AUTOSAR XML (schema 4-2-2)
package /AUTOLIV/SoftwareComponents/ACC
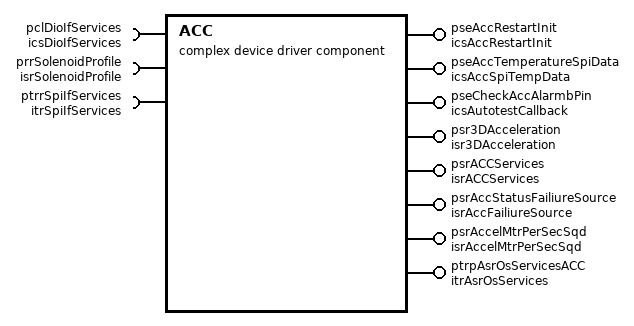
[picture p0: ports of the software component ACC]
  complex device driver sw component type ACC: category=MCAL_Communication_Abstraction
    require port pclDioIfServices: required-com-specs=[ReadChannel, WriteChannel], required-interface=icsDioIfServices  # # Architecture Element ID - ARCH_SW_ACC_pclDioIfServices # Description - The interface shall be used to read the state of ALARMB pin of TDK chip. # Data Flow ## Inputs - {u8ChannelID} - the ID of GPIO channel. ## Outputs - {u8Level} - the level of GPIO pin. # Linked Runnable - ACC_runMainFunction #Traceability
    require port prrSolenoidProfile: nonqueued-receiver-com-spec{data-element=au8SelectedProfile, init-value=6 x KU8_PROFILE_UNLOCK}, required-interface=isrSolenoidProfile
    8 x provide port:
      pseAccRestartInit: server-com-spec{operation=RestartInitialization, queue-length=1}, provided-interface=icsAccRestartInit  # # Architecture Element ID - ARCH_SW_ACC_pseAccRestartInit # Description - The runnable shall be used to restart the initialization sequence of TDK chip when ECU is restore from sleep mode. # Data Flow ## Inputs ## Outputs # Linked Runnable - ACC_RestartInitialization #Traceability
      pseAccTemperatureSpiData: server-com-spec{operation=GetTemperatureData, queue-length=1}, provided-interface=icsAccSpiTempData  # # Architecture Element ID - ARCH_SW_ACC_pseAccTemperatureSpiData # Description - The runnable shall communicate the raw register value for the temperature read from the TDK chip. # Data Flow ## Inputs ## Outputs - {Raw Temperature} # Linked Runnable - ACC_GetAccelerometerTemperature #Traceability
      pseCheckAccAlarmbPin: server-com-spec{operation=AutotestCallback, queue-length=1}, provided-interface=icsAutotestCallback  # Architecture Element ID - ARCH_SW_ACC_pseCheckAccAlarmbPin # Description - The autotest shall check if the ALARMB pin of the TDK accelerometer chip has been activated; - If any of the x, y, z axes of accelerometer have 30 consecutive identical values, - If the sequence of the ALARMB pin at initialisation is within the nominal timing parameters, - If any bit from alarm register is qualified. - Also the autotest shall check the two bits of return status from the Spi response and also checking if a Spi response has a wrong CRC. - If one or more bits of status information are qualified within 100ms then the result of autotest shall be NOK # Data Flow ## Inputs ## Outputs - {Autotest Result} - Can be one of the following values: OK, NOK, NOT DECIDED # Linked Runnable - ACC_Autotest_CheckAlarmbPin #Traceability DOM_eCS_TF_H_318 DOM_eCS_TF_H_319 DOM_eCS_TF_H_320
      psr3DAcceleration: nonqueued-sender-com-spec{data-element=st3DAccel, uses-end-to-end-protection=0, init-value=fields=[0, 0, 0]}, provided-interface=isr3DAcceleration  # # Architecture Element ID - ARCH_SW_ACC_psr3DAcceleration # Description - The runnable shall read the acceleration values for the x,y,z axis and communicate them to the rest of the Application raw values # Data Flow ## Inputs ## Outputs - {Acceleration} - Unit: g # Linked Runnable - ACC_runMainFunction #Traceability
      psrACCServices: nonqueued-sender-com-spec{data-element=u8AccInitStateMachine, uses-end-to-end-protection=0, init-value=0}, provided-interface=isrACCServices  # # Architecture Element ID - ARCH_SW_ACC_psrACCServices # Description - The runnable shall read the value of ACC initialization state machine index. # Data Flow ## Inputs - {acc_u8AccInitSM} - Variable used in ACC initialization state machine. ## Outputs # Linked Runnable - ACC_runMainFunction #Traceability
      psrAccStatusFailiureSource: provided-interface=isrAccFailiureSource  # # Architecture Element ID - ARCH_SW_ACC_psrAccStatusFailiureSource_u32AccAlarmRegStatus # Description - The runnable shall read all the data from alarm registers of accelerometer and write them to the {AlarmRegistersUsefulData} output parameter. # Data Flow ## Inputs ## Outputs - {AlarmRegistersUsefulData} - Unit: mapped bits # Linked Runnable - ACC_runMainFunction #Traceability FUSA_SM_ACC_DS-000342_IAM-20685_148 FUSA_SM_ACC_DS-000342_IAM-20685_149 FUSA_SM_ACC_DS-000342_IAM-20685_150 FUSA_SM_ACC_DS-000342_IAM-20685_151 DOM_eCS_TF_H_369 DOM_eCS_TF_H_359 DOM_eCS_TF_H_355 -------------------------------------------------------------------------------------------- # Architecture Element ID - ARCH_SW_ACC_psrAccStatusFailiureSource_u8AccReturnStatus # Description - The runnable shall read the two bits of return status received from Spi response of accelerometer. # Data Flow ## Inputs ## Outputs - {ReturnStatus} - Unit: two bits # Linked Runnable - ACC_runMainFunction #Traceability FUSA_SM_ACC_DS-000342_IAM-20685_134 --------------------------------------------------------------------------------------------- # Architecture Element ID - ARCH_SW_ACC_psrAccStatusFailiureSource_u8AccCRCStatus # Description - The runnable shall read the error status of CRC received from accelerometer. # Data Flow ## Inputs ## Outputs - {CRCStatus} - Unit: flag # Linked Runnable - ACC_runMainFunction #Traceability DOM_eCS_TF_H_318, DOM_eCS_TF_H_319 FUSA_SM_ACC_DS-000342_IAM-20685_134 ---------------------------------------------------------------------------------------------- # Architecture Element ID - ARCH_SW_ACC_psrAccStatusFailiureSource_u8AccAlarmbPreinitSeqStatus # Description - The runnable shall read the error status of ALARMB pin sequence at initialisation. # Data Flow ## Inputs ## Outputs - {AlarmbPreinitSeqStatus} - Unit: flag # Linked Runnable - ACC_runMainFunction #Traceability FUSA_SM_ACC_DS-000342_IAM-20685_128 FUSA_SM_ACC_DS-000342_IAM-20685_129 FUSA_SM_ACC_DS-000342_IAM-20685_130 FUSA_SM_ACC_DS-000342_IAM-20685_131 FUSA_SM_ACC_DS-000342_IAM-20685_132 FUSA_SM_ACC_DS-000342_IAM-20685_133 ---------------------------------------------------------------------------------------------- # Architecture Element ID - ARCH_SW_ACC_psrAccStatusFailiureSource_u8AccelAxisBroken # Description - The runnable shall read the error status of broken data from each accelerometer axis. # Data Flow ## Inputs ## Outputs - {AccelAxisBroken} - Unit: 3 flags (0b00000xyz) # Linked Runnable - ACC_runMainFunction #Traceability FUSA_SM_ACC_DS-000342_IAM-20685_141 ----------------------------------------------------------------------------------------------
        provided-com-specs:
          data-element=u32AccAlarmRegStatus, uses-end-to-end-protection=0, init-value=0
          data-element=u8AccCRCStatus, uses-end-to-end-protection=0, init-value=0
          data-element=u8AccReturnStatus, uses-end-to-end-protection=0, init-value=0
          data-element=u8AccelAxisBroken, uses-end-to-end-protection=0, init-value=0
          data-element=u8AccAlarmbPreinitSeqStatus, uses-end-to-end-protection=0, init-value=0
      psrAccelMtrPerSecSqd: nonqueued-sender-com-spec{data-element=stAccelMtrPerSecSqd, uses-end-to-end-protection=0, init-value=fields=[0, 0, 0]}, provided-interface=isrAccelMtrPerSecSqd  # # Architecture Element ID - ARCH_SW_ACC_psrAccelMtrPerSecSqd # Description - The runnable shall read the acceleration values for the x,y,z axis and communicate them to the rest of the Application in m/s sqd # Data Flow ## Inputs ## Outputs - {Acceleration} - Unit: m/s sqd # Linked Runnable - ACC_runMainFunction #Traceability
      ptrpAsrOsServicesACC: provided-interface=itrAsrOsServices  # # Architecture Element ID - ARCH_SW_ACC_ptrpAsrOsServices_ACC_runMainFunction # Description - The runnable shall be called periodically at 1 ms in order to facilitate communication with the accelerometer(to read the acceleration values) # Data Flow ## Inputs ## Outputs # Linked Runnable - ACC_runMainFunction #Traceability FUSA_DS_ACC_6604461_000_OCD_166 FUSA_DS_ACC_6604461_000_OCD_232 FUSA_DS_ACC_6604461_000_OCD_233 FUSA_DS_ACC_6604461_000_OCD_235 FUSA_DS_ACC_6604461_000_OCD_238 FUSA_DS_ACC_6604461_000_OCD_245 FUSA_DS_ACC_6604461_000_OCD_247 FUSA_DS_ACC_6604461_000_OCD_250 FUSA_DS_ACC_6604461_000_OCD_254 FUSA_DS_ACC_6604461_000_OCD_255 FUSA_DS_ACC_6604461_000_OCD_257 FUSA_DS_ACC_6604461_000_OCD_269 FUSA_DS_ACC_6604461_000_OCD_270 FUSA_DS_ACC_6604461_000_OCD_271 FUSA_DS_ACC_6604461_000_OCD_272 FUSA_DS_ACC_6604461_000_OCD_274 FUSA_DS_ACC_6604461_000_OCD_276 FUSA_DS_ACC_6604461_000_OCD_277 FUSA_DS_ACC_6604461_000_OCD_279 FUSA_DS_ACC_6604461_000_OCD_280 FUSA_DS_ACC_6604461_000_OCD_282 FUSA_DS_ACC_6604461_000_OCD_283 FUSA_DS_ACC_6604461_000_OCD_286 FUSA_DS_ACC_6604461_000_OCD_287 FUSA_DS_ACC_6604461_000_OCD_288 FUSA_DS_ACC_6604461_000_OCD_292 FUSA_DS_ACC_6604461_000_OCD_293 FUSA_DS_ACC_6604461_000_OCD_294 FUSA_DS_ACC_6604461_000_OCD_296 FUSA_DS_ACC_6604461_000_OCD_304 FUSA_DS_ACC_6604461_000_OCD_305 FUSA_DS_ACC_6604461_000_OCD_306 FUSA_DS_ACC_6604461_000_OCD_308 FUSA_DS_ACC_6604461_000_OCD_309 FUSA_DS_ACC_6604461_000_OCD_312 FUSA_DS_ACC_6604461_000_OCD_321 FUSA_DS_ACC_6604461_000_OCD_322 FUSA_DS_ACC_6604461_000_OCD_323 FUSA_DS_ACC_6604461_000_OCD_326 FUSA_DS_ACC_6604461_000_OCD_327 FUSA_DS_ACC_6604461_000_OCD_328 FUSA_DS_ACC_6604461_000_OCD_330 FUSA_DS_ACC_6604461_000_OCD_331 FUSA_DS_ACC_6604461_000_OCD_333 FUSA_DS_ACC_6604461_000_OCD_334 FUSA_DS_ACC_6604461_000_OCD_342 FUSA_DS_ACC_6604461_000_OCD_343 FUSA_DS_ACC_6604461_000_OCD_347 FUSA_DS_ACC_6604461_000_OCD_357 FUSA_DS_ACC_6604461_000_OCD_385 FUSA_DS_ACC_6604461_000_OCD_387 FUSA_DS_ACC_6604461_000_OCD_388 FUSA_DS_ACC_6604461_000_OCD_398 FUSA_DS_ACC_6604461_000_OCD_403 FUSA_DS_ACC_6604461_000_OCD_405 FUSA_DS_ACC_6604461_000_OCD_406 FUSA_DS_ACC_6604461_000_OCD_407 FUSA_DS_ACC_6604461_000_OCD_409 FUSA_DS_ACC_6604461_000_OCD_410 FUSA_DS_ACC_6604461_000_OCD_411 FUSA_DS_ACC_6604461_000_OCD_422 FUSA_DS_ACC_6604461_000_OCD_424 FUSA_DS_ACC_6604461_000_OCD_429 FUSA_DS_ACC_6604461_000_OCD_430 FUSA_DS_ACC_6604461_000_OCD_432 FUSA_SM_ACC_DS-000342_IAM-20685_180 FUSA_SM_ACC_DS-000342_IAM-20685_181 FUSA_SM_ACC_DS-000342_IAM-20685_182 FUSA_SM_ACC_DS-000342_IAM-20685_183 FUSA_SM_ACC_DS-000342_IAM-20685_190 FUSA_SM_ACC_DS-000342_IAM-20685_185 FUSA_SM_ACC_DS-000342_IAM-20685_186 FUSA_SM_ACC_DS-000342_IAM-20685_187 FUSA_SM_ACC_DS-000342_IAM-20685_188 FUSA_SM_ACC_DS-000342_IAM-20685_191 FUSA_SM_ACC_DS-000342_IAM-20685_193 FUSA_SM_ACC_DS-000342_IAM-20685_195 FUSA_SM_ACC_DS-000342_IAM-20685_196 FUSA_SM_ACC_DS-000342_IAM-20685_197 FUSA_SM_ACC_DS-000342_IAM-20685_198 FUSA_SM_ACC_DS-000342_IAM-20685_199 FUSA_SM_ACC_DS-000342_IAM-20685_200 FUSA_SM_ACC_DS-000342_IAM-20685_201 FUSA_SM_ACC_DS-000342_IAM-20685_202 FUSA_SM_ACC_DS-000342_IAM-20685_203 FUSA_SM_ACC_DS-000342_IAM-20685_204 FUSA_SM_ACC_DS-000342_IAM-20685_205 FUSA_SM_ACC_DS-000342_IAM-20685_206 FUSA_SM_ACC_DS-000342_IAM-20685_207 FUSA_SM_ACC_DS-000342_IAM-20685_208 FUSA_SM_ACC_DS-000342_IAM-20685_209 FUSA_SM_ACC_DS-000342_IAM-20685_211 FUSA_SM_ACC_DS-000342_IAM-20685_90 FUSA_SM_ACC_DS-000342_IAM-20685_95 FUSA_SM_ACC_DS-000342_IAM-20685_96 FUSA_SM_ACC_DS-000342_IAM-20685_97 FUSA_SM_ACC_DS-000342_IAM-20685_98 FUSA_SM_ACC_DS-000342_IAM-20685_101 FUSA_SM_ACC_DS-000342_IAM-20685_112 FUSA_SM_ACC_DS-000342_IAM-20685_134 FUSA_SM_ACC_DS-000342_IAM-20685_144 FUSA_SM_ACC_DS-000342_IAM-20685_148 FUSA_SM_ACC_DS-000342_IAM-20685_149 FUSA_SM_ACC_DS-000342_IAM-20685_150 FUSA_SM_ACC_DS-000342_IAM-20685_151 FUSA_SM_ACC_DS-000342_IAM-20685_127 FUSA_SM_ACC_DS-000342_IAM-20685_128 FUSA_SM_ACC_DS-000342_IAM-20685_129 FUSA_SM_ACC_DS-000342_IAM-20685_130 FUSA_SM_ACC_DS-000342_IAM-20685_131 FUSA_SM_ACC_DS-000342_IAM-20685_132 FUSA_SM_ACC_DS-000342_IAM-20685_141 ------------------------------------------------------------------------------------ # Architecture Element ID - ARCH_SW_ACC_ptrpAsrOsServices_ReadAccelerometerTemperature # Description - The runnable shall be called periodically at 40 ms in order to facilitate communication with the accelerometer(to read the temperature) # Data Flow ## Inputs ## Outputs # Linked Runnable - ACC_ReadAccelerometerTemperature #Traceability FUSA_DS_ACC_6604461_000_OCD_233 FUSA_DS_ACC_6604461_000_OCD_353 ------------------------------------------------------------------------------------ # Architecture Element ID ARCH_SW_ACC_ptrpAsrOsServicesACC_PORTE_ISR # Description - The PORTE_ISR runnable shall be called in the Os services runnable upon a hardware external interrupt # Data Flow # Linked Runnable - PORTE_ISR #Traceability FUSA_SM_ACC_DS-000342_IAM-20685_128 FUSA_SM_ACC_DS-000342_IAM-20685_129 FUSA_SM_ACC_DS-000342_IAM-20685_130 FUSA_SM_ACC_DS-000342_IAM-20685_131 FUSA_SM_ACC_DS-000342_IAM-20685_132 FUSA_SM_ACC_DS-000342_IAM-20685_133
    require port ptrrSpiIfServices: required-interface=itrSpiIfServices  # # Architecture Element ID - ARCH_SW_ACC_ptrrSpiIfServices_SpiIf_writeSpiData_ACC_ReadAccelerometerTemperature # Description - The runnable shall send spi command to read the temperature in ℃ from the acceleromenter via the SpiIf_writeSpiData interface # Data Flow ## Inputs ## Outputs # Linked Runnable - ACC_ReadAccelerometerTemperature #Traceability ------------------------------------------------------------------------------------ # Architecture Element ID - ARCH_SW_ACC_ptrrSpiIfServices_SpiIf_spiReadIBFromChannel_ACC_ReadAccelerometerTemperature # Description - The runnable shall read the spi response that contain the temperature in ℃ from the acceleromenter via the SpiIf_spiReadIBFromChannel interface # Data Flow ## Inputs ## Outputs # Linked Runnable - ACC_ReadAccelerometerTemperature #Traceability ------------------------------------------------------------------------------------ Architecture Element ID - ARCH_SW_ACC_ptrrSpiIfServices_SpiIf_writeSpiData_ACC_runMainFunction # Description - The runnable shall send Spi data to initialize the TDK chip # Data Flow ## Inputs ## Outputs # Linked Runnable - ACC_runMainFunction #Traceability ------------------------------------------------------------------------------------ Architecture Element ID - ARCH_SW_ACC_ptrrSpiIfServices_SpiIf_spiReadIBFromChannel_ACC_runMainFunction # Description - The runnable shall read the spi response that contain the data from settings registers or acceleration data registers # Data Flow ## Inputs ## Outputs # Linked Runnable - ACC_runMainFunction #Traceability ------------------------------------------------------------------------------------ Architecture Element ID - ARCH_SW_ACC_ptrrSpiIfServices_SpiIf_spiSyncTransmitSequence_ACC_runMainFunction # Description - The runnable shall send the spi sequience of commands to read 3 axis of acceleration # Data Flow ## Inputs ## Outputs # Linked Runnable - ACC_runMainFunction #Traceability
  sender receiver interface isrACCServices
    data u8AccInitStateMachine: type=UInt8_Appl
